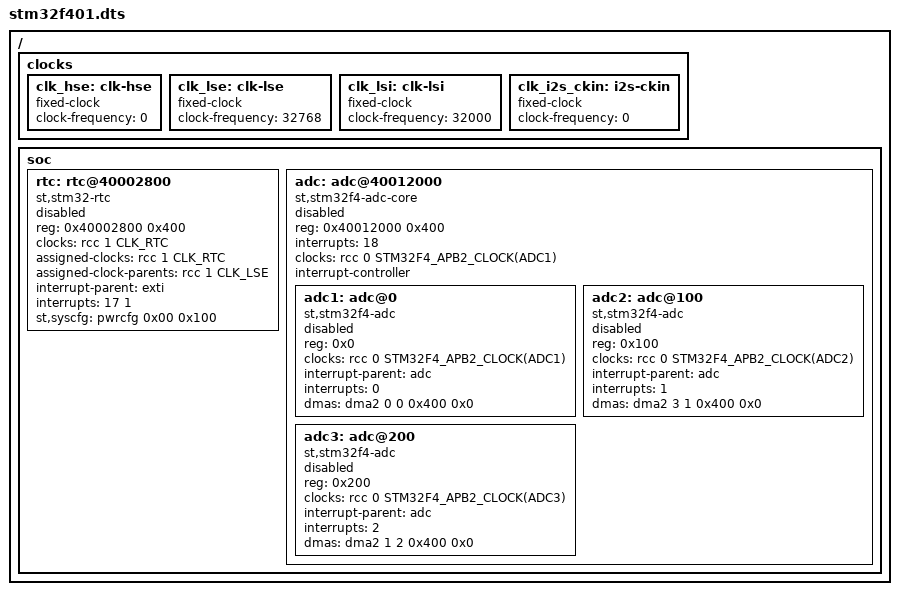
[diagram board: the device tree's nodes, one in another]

#include "armv7-m.dtsi"
#include <dt-bindings/clock/stm32fx-clock.h>
#include <dt-bindings/mfd/stm32f4-rcc.h>

/ {
    #address-cells = <1>;
    #size-cells = <1>;

    clocks {
        clk_hse: clk-hse {
        #clock-cells = <0>;
            compatible = "fixed-clock";
            clock-frequency = <0>;
        };

        clk_lse: clk-lse {
            #clock-cells = <0>;
            compatible = "fixed-clock";
            clock-frequency = <32768>;
        };

        clk_lsi: clk-lsi {
            #clock-cells = <0>;
            compatible = "fixed-clock";
            clock-frequency = <32000>;
        };

        clk_i2s_ckin: i2s-ckin {
            #clock-cells = <0>;
            compatible = "fixed-clock";
            clock-frequency = <0>;
        };
    };

    soc { 

        rtc: rtc@40002800 {
            compatible = "st,stm32-rtc";
            reg = <0x40002800 0x400>;
            clocks = <&rcc 1 CLK_RTC>;
            assigned-clocks = <&rcc 1 CLK_RTC>;
            assigned-clock-parents = <&rcc 1 CLK_LSE>;
            interrupt-parent = <&exti>;
            interrupts = <17 1>;
            st,syscfg = <&pwrcfg 0x00 0x100>;
            status = "disabled";
        };

        adc: adc@40012000 {
            compatible = "st,stm32f4-adc-core";
            reg = <0x40012000 0x400>;
            interrupts = <18>;
            clocks = <&rcc 0 STM32F4_APB2_CLOCK(ADC1)>;
            clock-names = "adc";
            interrupt-controller;
            #interrupt-cells = <1>;
            #address-cells = <1>;
            #size-cells = <0>;
            status = "disabled";

            adc1: adc@0 {
                compatible = "st,stm32f4-adc";
                #io-channel-cells = <1>;
                reg = <0x0>;
                clocks = <&rcc 0 STM32F4_APB2_CLOCK(ADC1)>;
                interrupt-parent = <&adc>;
                interrupts = <0>;
                dmas = <&dma2 0 0 0x400 0x0>;
                dma-names = "rx";
                status = "disabled";
            };

            adc2: adc@100 {
                compatible = "st,stm32f4-adc";
                #io-channel-cells = <1>;
                reg = <0x100>;
                clocks = <&rcc 0 STM32F4_APB2_CLOCK(ADC2)>;
                interrupt-parent = <&adc>;
                interrupts = <1>;
                dmas = <&dma2 3 1 0x400 0x0>;
                dma-names = "rx";
                status = "disabled";
            };

            adc3: adc@200 {
                compatible = "st,stm32f4-adc";
                #io-channel-cells = <1>;
                reg = <0x200>;
                clocks = <&rcc 0 STM32F4_APB2_CLOCK(ADC3)>;
                interrupt-parent = <&adc>;
                interrupts = <2>;
                dmas = <&dma2 1 2 0x400 0x0>;
                dma-names = "rx";
                status = "disabled";
            };
        };

    };
    
};
